# LKS32MC03x register map
Vendor: Linko Ltd.; Series: LKS32MC03x; File version: 1.0
CPU: CM0 r1p0, little endian, MPU, no FPU, 3 interrupt priority bits
Registers are 32-bit, read-write, reset 0x0 unless marked. A register's access mark holds for its fields unless they carry their own. Offsets are from the block's base; [hi:lo] are bit positions; {n}, {i} and the like mark numbered series; 'fields as' and 'values as' point back to an identical list.

## UTIMER0 — UTIMER0 registers
Base 0x40010500
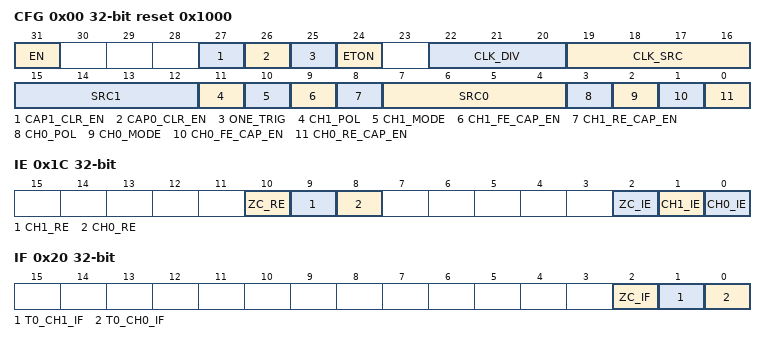
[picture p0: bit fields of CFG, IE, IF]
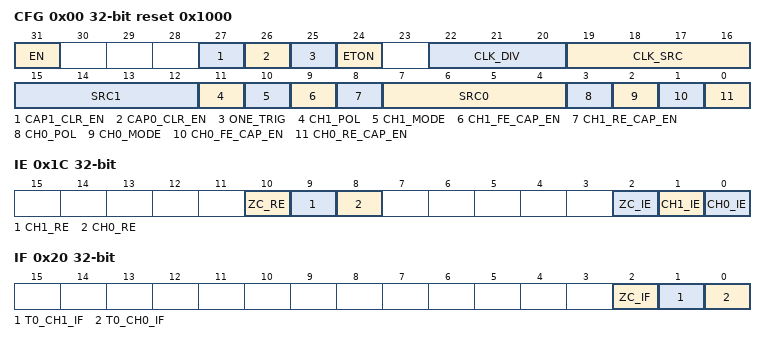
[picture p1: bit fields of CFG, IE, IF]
0x00 CFG reset 0x1000 — Timer configuration
  [31] EN — Timer enable
  [27] CAP1_CLR_EN — clear timer cnt when CAP1
  [26] CAP0_CLR_EN — clear timer cnt when CAP0
  [25] ONE_TRIG — trigger timer to send for one period
  [24] ETON — Timer external trigger
    0=IT (Free run); 1=ET (Extrenal trigger)
  [22:20] CLK_DIV — Timer clock division ratio
    0=DIV1 (Main clock no division); 1=DIV2 (Main clock divided by 2); 2=DIV4 (Main clock divided by 4); 3=DIV8 (Main clock divided by 8); 4=DIV16 (Main clock divided by 16); 5=DIV32 (Main clock divided by 32); 6=DIV64 (Main clock divided by 64); 7=DIV128 (Main clock divided by 128)
  [19:16] CLK_SRC — Timer clock source
    0=SYSCLK (internal system clock); 2=T0_CH0 (timer0 ch0); 3=T0_CH1 (timer0 ch1); 4=T1_CH0 (timer1 ch0); 5=T1_CH1 (timer1 ch1)
  [15:12] SRC1 — Timer capture mode ch1 source
    0=CH0 (timer ch0); 1=CH1 (timer ch1); 2=CMP0 (Comparator 0 output); 3=CMP1 (Comparator 1 output); 8=CH01XOR (timer ch0^ch1)
  [11] CH1_POL — Channel 1 output polarity at zero-crossing in comparision mode
    0=L (Output 0); 1=H (Output 1)
  [10] CH1_MODE — Channel 1 mode
    0=CMP (Comparison mode); 1=CAP (Capture mode)
  [9] CH1_FE_CAP_EN — Channel 1 falling edge capture enable
    0=DISABLED (Falling edge event disabled); 1=ENABLED (Falling edge event enabled)
  [8] CH1_RE_CAP_EN — Channel 1 rising edge capture enable
    0=DISABLED (Rising edge event disabled); 1=ENABLED (Rising edge event enabled)
  [7:4] SRC0 — Timer capture mode ch0 source
    values as SRC1
  [3] CH0_POL — Channel 0 output polarity at zero-crossing in comparision mode
    0=L (Output 0); 1=H (Output 1)
  [2] CH0_MODE — Channel 0 mode
    0=CMP (Comparison mode); 1=CAP (Capture mode)
  [1] CH0_FE_CAP_EN — Channel 0 falling edge capture enable
    values as CH1_FE_CAP_EN
  [0] CH0_RE_CAP_EN — Channel 0 rising edge capture enable
    values as CH1_RE_CAP_EN
0x04 TH — Timer counter threshold, timer will count from 0 to TH, then over again
  [15:0] TH — Timer counter threshold
0x08 CNT — Timer current counter value (write to set)
  [15:0] CNT — Timer counter value
0x0C CMP0 — Timer Channel0 CMP/CAP threshold
  [15:0] CMP0
0x10 CMP1 — Timer Channel1 CMP/CAP threshold
  [15:0] CMP1
0x14 EVT — Timer External Trigger Event
  [4:0] SRC — external event select
    0=T0_CH0 (Use timer0 channel 0 as trigger); 1=T0_CH1 (Use timer0 channel 1 as trigger); 2=T1_CH0 (Use timer1 channel 0 as trigger); 3=T1_CH1 (Use timer1 channel 1 as trigger); {v}=MCPWM_TADC{v-10} (Use MCPWM TADC{v-10} as trigger) (v=10..13)
0x18 FLT — Timer Filter Width (FLT*8 timer clock cycles)
  [7:0] FLT — Filter width
0x1C IE — Timer Interrupt Enable
  [10] ZC_RE — Zero cross DMA request enable
  [9] CH1_RE — ch1 cmp/cap dma request enable
  [8] CH0_RE — ch0 cmp/cap dma request enable
  [2] ZC_IE — Zero cross interrupt request enable
  [1] CH1_IE — ch1 cmp/cap interrupt request enable
  [0] CH0_IE — ch0 cmp/cap interrupt request enable
0x20 IF — Timer Interrupt Flag
  [2] ZC_IF — Zero cross interrupt flag
  [1] T0_CH1_IF — ch1 cmp/cap interrupt flag
  [0] T0_CH0_IF — ch0 cmp/cap interrupt flag

## UTIMER1 — UTIMER1 registers
Base 0x40010600
0x00 CFG reset 0x1000 — Timer configuration
  [31] EN — Timer enable
  [27] CAP1_CLR_EN — clear timer cnt when CAP1
  [26] CAP0_CLR_EN — clear timer cnt when CAP0
  [25] ONE_TRIG — trigger timer to send for one period
  [24] ETON — Timer external trigger
    0=IT (Free run); 1=ET (Extrenal trigger)
  [22:20] CLK_DIV — Timer clock division ratio
    0=DIV1 (Main clock no division); 1=DIV2 (Main clock divided by 2); 2=DIV4 (Main clock divided by 4); 3=DIV8 (Main clock divided by 8); 4=DIV16 (Main clock divided by 16); 5=DIV32 (Main clock divided by 32); 6=DIV64 (Main clock divided by 64); 7=DIV128 (Main clock divided by 128)
  [19:16] CLK_SRC — Timer clock source
    0=SYSCLK (internal system clock); 2=T0_CH0 (timer0 ch0); 3=T0_CH1 (timer0 ch1); 4=T1_CH0 (timer1 ch0); 5=T1_CH1 (timer1 ch1)
  [15:12] SRC1 — Timer capture mode ch1 source
    0=CH0 (timer ch0); 1=CH1 (timer ch1); 2=CMP0 (Comparator 0 output); 3=CMP1 (Comparator 1 output); 8=CH01XOR (timer ch0^ch1)
  [11] CH1_POL — Channel 1 output polarity at zero-crossing in comparision mode
    0=L (Output 0); 1=H (Output 1)
  [10] CH1_MODE — Channel 1 mode
    0=CMP (Comparison mode); 1=CAP (Capture mode)
  [9] CH1_FE_CAP_EN — Channel 1 falling edge capture enable
    0=Disabled (Falling edge event disabled); 1=Enabled (Falling edge event enabled)
  [8] CH1_RE_CAP_EN — Channel 1 rising edge capture enable
    0=Disabled (Rising edge event disabled); 1=Enabled (Rising edge event enabled)
  [7:4] SRC0 — Timer capture mode ch0 source
    values as SRC1
  [3] CH0_POL — Channel 0 output polarity at zero-crossing in comparision mode
    0=L (Output 0); 1=H (Output 1)
  [2] CH0_MODE — Channel 0 mode
    0=CMP (Comparison mode); 1=CAP (Capture mode)
  [1] CH0_FE_CAP_EN — Channel 0 falling edge capture enable
    values as CH1_FE_CAP_EN
  [0] CH0_RE_CAP_EN — Channel 0 rising edge capture enable
    values as CH1_RE_CAP_EN
0x04 TH — Timer counter threshold, timer will count from 0 to TH, then over again
  [31:0] TH — Timer counter threshold
0x08 CNT — Timer current counter value (write to set)
  [31:0] CNT — Timer counter value
0x0C CMP0 — Timer Channel0 CMP/CAP threshold
0x10 CMP1 — Timer Channel1 CMP/CAP threshold
0x14 EVT — Timer External Trigger Event
  [4:0] SRC — external event select
    0=T0_CH0 (Use timer0 channel 0 as trigger); 1=T0_CH1 (Use timer0 channel 1 as trigger); 2=T1_CH0 (Use timer1 channel 0 as trigger); 3=T1_CH1 (Use timer1 channel 1 as trigger); {v}=MCPWM_TADC{v-10} (Use MCPWM TADC{v-10} as trigger) (v=10..13)
0x18 FLT — Timer Filter Width (FLT*8 timer clock cycles)
  [7:0] FLT — Filter width
0x1C IE — Timer Interrupt Enable
  [10] ZC_RE — Zero cross DMA request enable
  [9] CH1_RE — ch1 cmp/cap dma request enable
  [8] CH0_RE — ch0 cmp/cap dma request enable
  [2] ZC_IE — Zero cross interrupt request enable
  [1] CH1_IE — ch1 cmp/cap interrupt request enable
  [0] CH0_IE — ch0 cmp/cap interrupt request enable
0x20 IF — Timer Interrupt Flag
  [2] ZC_IF — Zero cross interrupt flag
  [1] T0_CH1_IF — ch1 cmp/cap interrupt flag
  [0] T0_CH0_IF — ch0 cmp/cap interrupt flag
